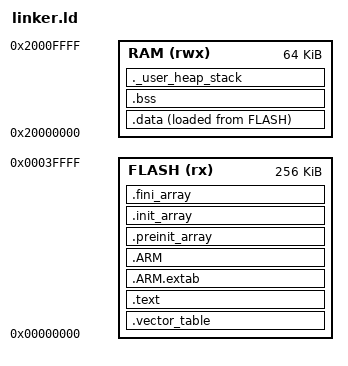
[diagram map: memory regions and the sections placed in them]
/* =============================================================================
 * Universal Linker Script for ARM Cortex-M QEMU Semihosting Emulation
 * Supports Cortex-M3 (lm3s6965evb), Cortex-M4 (mps2-an386), Cortex-M7 (mps2-an500)
 * ============================================================================= */

ENTRY(Reset_Handler)

MEMORY
{
    FLASH (rx)  : ORIGIN = 0x00000000, LENGTH = 256K
    RAM   (rwx) : ORIGIN = 0x20000000, LENGTH = 64K
}

_estack = ORIGIN(RAM) + LENGTH(RAM);

SECTIONS
{
    .vector_table :
    {
        . = ALIGN(4);
        KEEP(*(.vector_table))
        . = ALIGN(4);
    } > FLASH

    .text :
    {
        . = ALIGN(4);
        *(.text)
        *(.text*)
        *(.rodata)
        *(.rodata*)
        *(.glue_7)
        *(.glue_7t)
        *(.eh_frame)
        KEEP (*(.init))
        KEEP (*(.fini))
        . = ALIGN(4);
        _etext = .;
    } > FLASH

    .ARM.extab : { *(.ARM.extab* .gnu.linkonce.armextab.*) } > FLASH
    .ARM : {
        __exidx_start = .;
        *(.ARM.exidx*)
        __exidx_end = .;
    } > FLASH

    .preinit_array :
    {
        PROVIDE_HIDDEN (__preinit_array_start = .);
        KEEP (*(.preinit_array*))
        PROVIDE_HIDDEN (__preinit_array_end = .);
    } > FLASH

    .init_array :
    {
        PROVIDE_HIDDEN (__init_array_start = .);
        KEEP (*(SORT(.init_array.*)))
        KEEP (*(.init_array*))
        PROVIDE_HIDDEN (__init_array_end = .);
    } > FLASH

    .fini_array :
    {
        PROVIDE_HIDDEN (__fini_array_start = .);
        KEEP (*(SORT(.fini_array.*)))
        KEEP (*(.fini_array*))
        PROVIDE_HIDDEN (__fini_array_end = .);
    } > FLASH

    _sidata = LOADADDR(.data);

    .data :
    {
        . = ALIGN(4);
        _sdata = .;
        *(.data)
        *(.data*)
        . = ALIGN(4);
        _edata = .;
    } > RAM AT> FLASH

    .bss :
    {
        . = ALIGN(4);
        _sbss = .;
        __bss_start__ = _sbss;
        *(.bss)
        *(.bss*)
        *(COMMON)
        . = ALIGN(4);
        _ebss = .;
        __bss_end__ = _ebss;
    } > RAM

    ._user_heap_stack :
    {
        . = ALIGN(8);
        PROVIDE ( end = . );
        PROVIDE ( _end = . );
        . = . + 0x2000;
        . = ALIGN(8);
    } > RAM
}
